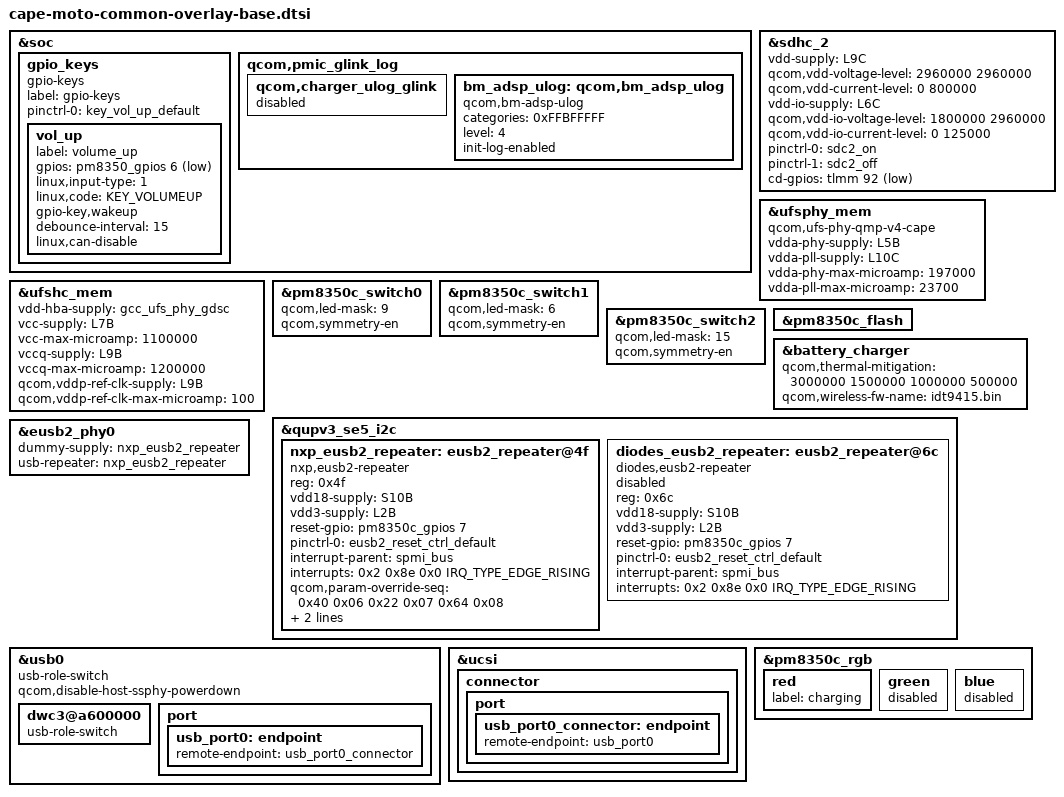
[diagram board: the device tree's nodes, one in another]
/* Copyright (c) 2022, The Linux Foundation. All rights reserved.
 *
 * This program is free software; you can redistribute it and/or modify
 * it under the terms of the GNU General Public License version 2 and
 * only version 2 as published by the Free Software Foundation.
 *
 * This program is distributed in the hope that it will be useful,
 * but WITHOUT ANY WARRANTY; without even the implied warranty of
 * MERCHANTABILITY or FITNESS FOR A PARTICULAR PURPOSE.  See the
 * GNU General Public License for more details.
 */

/*
   This base is original from "cape-mtp.dtsi"
*/

#include <dt-bindings/gpio/gpio.h>
#include <dt-bindings/input/input.h>
#include "cape-pmic-overlay.dtsi"
#include "waipio-thermal-overlay.dtsi"

&soc {
	gpio_keys {
		compatible = "gpio-keys";
		label = "gpio-keys";

		pinctrl-names = "default";
		pinctrl-0 = <&key_vol_up_default>;

		vol_up {
			label = "volume_up";
			gpios = <&pm8350_gpios 6 GPIO_ACTIVE_LOW>;
			linux,input-type = <1>;
			linux,code = <KEY_VOLUMEUP>;
			gpio-key,wakeup;
			debounce-interval = <15>;
			linux,can-disable;
		};
	};

	qcom,pmic_glink_log {
		qcom,charger_ulog_glink {
			status = "disabled";
		};
		bm_adsp_ulog: qcom,bm_adsp_ulog {
			compatible = "qcom,bm-adsp-ulog";
			categories = <0xFFBFFFFF>;
			level = <4>;
			init-log-enabled;
		};
	};
};

&sdhc_2 {
	status = "ok";
	vdd-supply = <&L9C>;
	qcom,vdd-voltage-level = <2960000 2960000>;
	qcom,vdd-current-level = <0 800000>;

	vdd-io-supply = <&L6C>;
	qcom,vdd-io-voltage-level = <1800000 2960000>;
	qcom,vdd-io-current-level = <0 125000>;

	pinctrl-names = "default", "sleep";
	pinctrl-0 = <&sdc2_on>;
	pinctrl-1 = <&sdc2_off>;

	cd-gpios = <&tlmm 92 GPIO_ACTIVE_LOW>;
};

&ufsphy_mem {
	compatible = "qcom,ufs-phy-qmp-v4-cape";

	vdda-phy-supply = <&L5B>;
	vdda-pll-supply = <&L10C>;
	vdda-phy-max-microamp = <197000>;
	vdda-pll-max-microamp = <23700>;

	status = "ok";
};

&ufshc_mem {
	vdd-hba-supply = <&gcc_ufs_phy_gdsc>;

	vcc-supply = <&L7B>;
	vcc-max-microamp = <1100000>;

	vccq-supply = <&L9B>;
	vccq-max-microamp = <1200000>;

	qcom,vddp-ref-clk-supply = <&L9B>;
	qcom,vddp-ref-clk-max-microamp = <100>;

	status = "ok";
};

&pm8350c_switch0 {
	qcom,led-mask = <9>; /* Channels 1 & 4 */
	qcom,symmetry-en;
};

&pm8350c_switch1 {
	qcom,led-mask = <6>; /* Channels 2 & 3 */
	qcom,symmetry-en;
};

&pm8350c_switch2 {
	qcom,led-mask = <15>; /* All Channels */
	qcom,symmetry-en;
};

&pm8350c_flash {
	status = "ok";
};

&battery_charger {
	qcom,thermal-mitigation = <3000000 1500000 1000000 500000>;
	qcom,wireless-fw-name = "idt9415.bin";
};

&qupv3_se5_i2c {
	status = "ok";

	#address-cells = <1>;
	#size-cells = <0>;
	nxp_eusb2_repeater: eusb2_repeater@4f {
		compatible = "nxp,eusb2-repeater";
		reg = <0x4f>;
		vdd18-supply = <&S10B>;
		vdd3-supply = <&L2B>;
		reset-gpio = <&pm8350c_gpios 7 GPIO_ACTIVE_HIGH>;
		pinctrl-names = "default";
		pinctrl-0 = <&eusb2_reset_ctrl_default>;
		interrupt-parent = <&spmi_bus>;
		interrupts = <0x2 0x8e 0x0 IRQ_TYPE_EDGE_RISING>;
		interrupt-names = "eusb2_rptr_reset_gpio_irq";
		qcom,param-override-seq = <0x40 0x06
					   0x22 0x07
					   0x64 0x08>;
		qcom,host-param-override-seq = <0x40 0x06
						0x22 0x07
						0x24 0x08>;
	};
	diodes_eusb2_repeater: eusb2_repeater@6c {
		compatible = "diodes,eusb2-repeater";
		reg = <0x6c>;
		vdd18-supply = <&S10B>;
		vdd3-supply = <&L2B>;
		reset-gpio = <&pm8350c_gpios 7 GPIO_ACTIVE_HIGH>;
		pinctrl-names = "default";
		pinctrl-0 = <&eusb2_reset_ctrl_default>;
		interrupt-parent = <&spmi_bus>;
		interrupts = <0x2 0x8e 0x0 IRQ_TYPE_EDGE_RISING>;
		interrupt-names = "eusb2_rptr_reset_gpio_irq";
		status = "disabled";
	};
};

&eusb2_phy0 {
	dummy-supply = <&nxp_eusb2_repeater>;
	usb-repeater = <&nxp_eusb2_repeater>;
};

&usb0 {
	usb-role-switch;
        qcom,disable-host-ssphy-powerdown;
	dwc3@a600000 {
		usb-role-switch;
	};

	port {
		usb_port0: endpoint {
			remote-endpoint = <&usb_port0_connector>;
		};
	};
};

&ucsi {
	connector {
		port {
			usb_port0_connector: endpoint {
				remote-endpoint = <&usb_port0>;
			};
		};
	};
};

&pm8350c_rgb {
	red {
		label = "charging";
	};

	green {
		status = "disabled";
	};

	blue {
		status = "disabled";
	};
};
